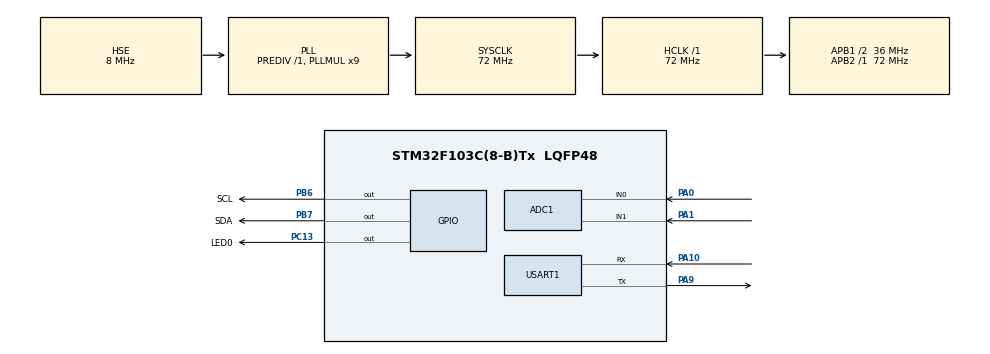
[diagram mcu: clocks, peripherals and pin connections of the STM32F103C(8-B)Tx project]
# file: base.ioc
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ADC1.Channel-6\#ChannelRegularConversion=ADC_CHANNEL_0
ADC1.Channel-8\#ChannelRegularConversion=ADC_CHANNEL_1
ADC1.ContinuousConvMode=ENABLE
ADC1.ExternalTrigConv=ADC_SOFTWARE_START
ADC1.NbrOfConversion=2
ADC1.NbrOfConversionFlag=1
ADC1.Rank-6\#ChannelRegularConversion=1
ADC1.Rank-8\#ChannelRegularConversion=2
ADC1.SamplingTime-6\#ChannelRegularConversion=ADC_SAMPLETIME_7CYCLES_5
ADC1.SamplingTime-8\#ChannelRegularConversion=ADC_SAMPLETIME_7CYCLES_5
ADC1.master=1
Dma.ADC1.0.Direction=DMA_PERIPH_TO_MEMORY
Dma.ADC1.0.Instance=DMA1_Channel1
Dma.ADC1.0.MemDataAlignment=DMA_MDATAALIGN_HALFWORD
Dma.ADC1.0.MemInc=DMA_MINC_ENABLE
Dma.ADC1.0.Mode=DMA_CIRCULAR
Dma.ADC1.0.PeriphDataAlignment=DMA_PDATAALIGN_HALFWORD
Dma.ADC1.0.PeriphInc=DMA_PINC_DISABLE
Dma.ADC1.0.Priority=DMA_PRIORITY_LOW
Dma.Request0=ADC1
Mcu.Family=STM32F1
Mcu.Name=STM32F103C(8-B)Tx
Mcu.Package=LQFP48
NVIC.ADC1_2_IRQn=true\:0\:0\:false\:false\:true\:true\:true
NVIC.DMA1_Channel1_IRQn=true\:0\:0\:false\:false\:true\:false\:true
NVIC.PriorityGroup=NVIC_PRIORITYGROUP_4
NVIC.TIM3_IRQn=true\:0\:0\:false\:false\:true\:true\:true
PA0-WKUP.Signal=ADCx_IN0
PA1.Signal=ADCx_IN1
PA10.Mode=Asynchronous
PA10.Signal=USART1_RX
PA9.Mode=Asynchronous
PA9.Signal=USART1_TX
PB6.GPIO_Label=SCL
PB6.Signal=GPIO_Output
PB7.GPIO_Label=SDA
PB7.Signal=GPIO_Output
PC13-TAMPER-RTC.GPIO_Label=LED0
PC13-TAMPER-RTC.GPIO_ModeDefaultOutputPP=GPIO_MODE_OUTPUT_PP
PC13-TAMPER-RTC.GPIO_PuPd=GPIO_NOPULL
PC13-TAMPER-RTC.Signal=GPIO_Output
PD0-OSC_IN.Mode=HSE-External-Oscillator
PD0-OSC_IN.Signal=RCC_OSC_IN
PD1-OSC_OUT.Mode=HSE-External-Oscillator
PD1-OSC_OUT.Signal=RCC_OSC_OUT
ProjectManager.HeapSize=0x200
ProjectManager.StackSize=0x400
ProjectManager.TargetToolchain=MDK-ARM V5
RCC.ADCPresc=RCC_ADCPCLK2_DIV6
RCC.AHBFreq_Value=72000000
RCC.APB1CLKDivider=RCC_HCLK_DIV2
RCC.APB1Freq_Value=36000000
RCC.APB1TimFreq_Value=72000000
RCC.APB2Freq_Value=72000000
RCC.APB2TimFreq_Value=72000000
RCC.HCLKFreq_Value=72000000
RCC.PLLMUL=RCC_PLL_MUL9
RCC.PLLSourceVirtual=RCC_PLLSOURCE_HSE
RCC.SYSCLKFreq_VALUE=72000000
RCC.SYSCLKSource=RCC_SYSCLKSOURCE_PLLCLK
RCC.USBFreq_Value=72000000
SH.ADCx_IN0.0=ADC1_IN0,IN0
SH.ADCx_IN1.0=ADC1_IN1,IN1
TIM3.Period=10000
TIM3.Prescaler=7200-1
USART1.VirtualMode=VM_ASYNC
VP_SYS_VS_ND.Mode=No_Debug
VP_TIM3_VS_ClockSourceINT.Mode=Internal
board=custom

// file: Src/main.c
/* USER CODE BEGIN Header */
/**
  ******************************************************************************
  * @file           : main.c
  * @brief          : Main program body
  ******************************************************************************
  * @attention
  *
  * Copyright (c) 2022 STMicroelectronics.
  * All rights reserved.
  *
  * This software is licensed under terms that can be found in the LICENSE file
  * in the root directory of this software component.
  * If no LICENSE file comes with this software, it is provided AS-IS.
  *
  ******************************************************************************
  */
/* USER CODE END Header */
#include "main.h"
#include "adc.h"
#include "dma.h"
#include "tim.h"
#include "usart.h"
#include "gpio.h"

/* USER CODE BEGIN Includes */
#include "stdio.h"
#include "joystick.h"
#include "oled.h"
#include "snake.h"
/* USER CODE END Includes */

void SystemClock_Config(void);

/* USER CODE BEGIN 0 */
//#define DEBUG 1
unsigned short ADC_Value = 0;
unsigned short ADC_Volt = 0;
unsigned short adc_buff[50] = {0};

/* USER CODE END 0 */

int main(void)
{

  /* MCU Configuration--------------------------------------------------------*/

  /* Reset of all peripherals, Initializes the Flash interface and the Systick. */
  HAL_Init();

  /* Configure the system clock */
  SystemClock_Config();

  /* Initialize all configured peripherals */
  MX_GPIO_Init();
  MX_USART1_UART_Init();
  MX_DMA_Init();
  MX_ADC1_Init();
  MX_TIM3_Init();
  /* USER CODE BEGIN 2 */
	HAL_ADCEx_Calibration_Start(&hadc1);
	HAL_ADC_Start_DMA(&hadc1, (unsigned int*)&adc_buff, 50);

	HAL_TIM_Base_Start_IT(&htim3);
	OLED_Init();
	GameInit();
	GameDraw();
  /* USER CODE END 2 */

  /* Infinite loop */
  while (1)
  {

    /* USER CODE BEGIN 3 */
		SnakeGame();
  }
  /* USER CODE END 3 */
}

void SystemClock_Config(void)
{
  RCC_OscInitTypeDef RCC_OscInitStruct = {0};
  RCC_ClkInitTypeDef RCC_ClkInitStruct = {0};
  RCC_PeriphCLKInitTypeDef PeriphClkInit = {0};

  /** Initializes the RCC Oscillators according to the specified parameters
  * in the RCC_OscInitTypeDef structure.
  */
  RCC_OscInitStruct.OscillatorType = RCC_OSCILLATORTYPE_HSE;
  RCC_OscInitStruct.HSEState = RCC_HSE_ON;
  RCC_OscInitStruct.HSEPredivValue = RCC_HSE_PREDIV_DIV1;
  RCC_OscInitStruct.HSIState = RCC_HSI_ON;
  RCC_OscInitStruct.PLL.PLLState = RCC_PLL_ON;
  RCC_OscInitStruct.PLL.PLLSource = RCC_PLLSOURCE_HSE;
  RCC_OscInitStruct.PLL.PLLMUL = RCC_PLL_MUL9;
  if (HAL_RCC_OscConfig(&RCC_OscInitStruct) != HAL_OK)
  {
    Error_Handler();
  }
  /** Initializes the CPU, AHB and APB buses clocks
  */
  RCC_ClkInitStruct.ClockType = RCC_CLOCKTYPE_HCLK|RCC_CLOCKTYPE_SYSCLK
                              |RCC_CLOCKTYPE_PCLK1|RCC_CLOCKTYPE_PCLK2;
  RCC_ClkInitStruct.SYSCLKSource = RCC_SYSCLKSOURCE_PLLCLK;
  RCC_ClkInitStruct.AHBCLKDivider = RCC_SYSCLK_DIV1;
  RCC_ClkInitStruct.APB1CLKDivider = RCC_HCLK_DIV2;
  RCC_ClkInitStruct.APB2CLKDivider = RCC_HCLK_DIV1;

  if (HAL_RCC_ClockConfig(&RCC_ClkInitStruct, FLASH_LATENCY_2) != HAL_OK)
  {
    Error_Handler();
  }
  PeriphClkInit.PeriphClockSelection = RCC_PERIPHCLK_ADC;
  PeriphClkInit.AdcClockSelection = RCC_ADCPCLK2_DIV6;
  if (HAL_RCCEx_PeriphCLKConfig(&PeriphClkInit) != HAL_OK)
  {
    Error_Handler();
  }
}

void Error_Handler(void)
{
  __disable_irq();
  while (1)
  {
  }
}
